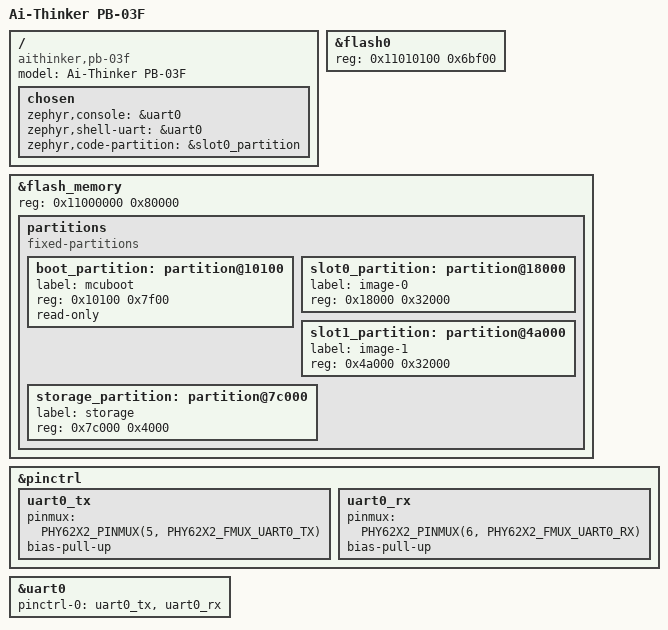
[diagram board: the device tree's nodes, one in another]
/*
 * SPDX-FileCopyrightText: Copyright The Zephyr Project Contributors
 * SPDX-License-Identifier: Apache-2.0
 */

/dts-v1/;

#include <phyplus/phy62x2.dtsi>

/ {
	model = "Ai-Thinker PB-03F";
	compatible = "aithinker,pb-03f";

	chosen {
		zephyr,console = &uart0;
		zephyr,shell-uart = &uart0;
		zephyr,code-partition = &slot0_partition;
	};
};

/* The application, up to the storage partition at the end of the 512 KiB flash */
&flash0 {
	reg = <0x11010100 0x6bf00>;
};

&flash_memory {
	reg = <0x11000000 0x80000>;

	partitions {
		compatible = "fixed-partitions";
		#address-cells = <1>;
		#size-cells = <1>;

		/* MCUboot at 0x10100, XIP, then two slots of the same size for the swap */
		boot_partition: partition@10100 {
			label = "mcuboot";
			reg = <0x10100 0x7f00>;
			read-only;
		};

		slot0_partition: partition@18000 {
			label = "image-0";
			reg = <0x18000 0x32000>;
		};

		slot1_partition: partition@4a000 {
			label = "image-1";
			reg = <0x4a000 0x32000>;
		};

		/* The NV of the application: four sectors, the frame counter wears them */
		storage_partition: partition@7c000 {
			label = "storage";
			reg = <0x7c000 0x4000>;
		};
	};
};

/* UART0 on P9 (TX) and P10 (RX), the pins of the boot ROM loader, which look for its string on P10 */
&pinctrl {
	uart0_tx: uart0_tx {
		pinmux = <PHY62X2_PINMUX(5, PHY62X2_FMUX_UART0_TX)>;
		bias-pull-up;
	};

	uart0_rx: uart0_rx {
		pinmux = <PHY62X2_PINMUX(6, PHY62X2_FMUX_UART0_RX)>;
		bias-pull-up;
	};
};

&uart0 {
	pinctrl-0 = <&uart0_tx &uart0_rx>;
	pinctrl-names = "default";
	status = "okay";
};
